# M2Sxxx register map
Vendor: Microsemi; Series: SmartFusion2; File version: 2.0.32
CPU: CM3 r2p1, little endian, MPU, no FPU, 4 interrupt priority bits
Registers are 32-bit, read-write, no defined reset value unless marked. A register's access mark holds for its fields unless they carry their own. Offsets are from the block's base; [hi:lo] are bit positions; {n}, {i} and the like mark numbered series; 'fields as' and 'values as' point back to an identical list.

## MDDR — No description provided for this peripheral
Base 0x40020800
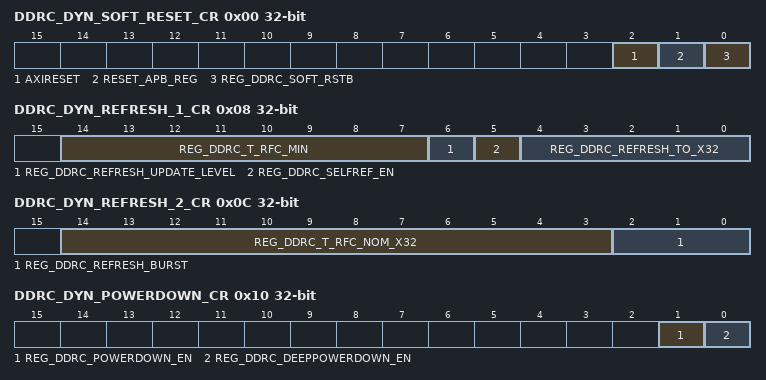
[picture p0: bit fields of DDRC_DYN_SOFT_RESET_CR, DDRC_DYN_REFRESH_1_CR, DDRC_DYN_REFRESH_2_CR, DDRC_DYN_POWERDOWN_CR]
0x00 DDRC_DYN_SOFT_RESET_CR — No description provided for this register
  [2] AXIRESET — No description provided for this field
  [1] RESET_APB_REG — No description provided for this field
  [0] REG_DDRC_SOFT_RSTB — No description provided for this field
0x08 DDRC_DYN_REFRESH_1_CR — No description provided for this register
  [14:7] REG_DDRC_T_RFC_MIN — No description provided for this field
  [6] REG_DDRC_REFRESH_UPDATE_LEVEL — No description provided for this field
  [5] REG_DDRC_SELFREF_EN — No description provided for this field
  [4:0] REG_DDRC_REFRESH_TO_X32 — No description provided for this field
0x0C DDRC_DYN_REFRESH_2_CR — No description provided for this register
  [14:3] REG_DDRC_T_RFC_NOM_X32 — No description provided for this field
  [2:0] REG_DDRC_REFRESH_BURST — No description provided for this field
0x10 DDRC_DYN_POWERDOWN_CR — No description provided for this register
  [1] REG_DDRC_POWERDOWN_EN — No description provided for this field
  [0] REG_DDRC_DEEPPOWERDOWN_EN — No description provided for this field
0x14 DDRC_DYN_DEBUG_CR — No description provided for this register
  [0] REG_DDRC_DIS_DQ — No description provided for this field
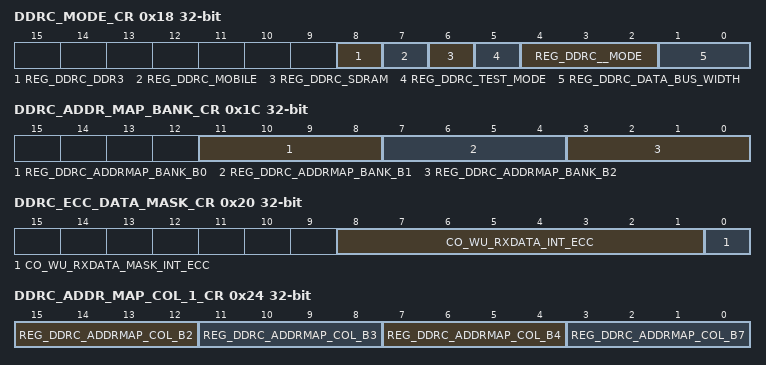
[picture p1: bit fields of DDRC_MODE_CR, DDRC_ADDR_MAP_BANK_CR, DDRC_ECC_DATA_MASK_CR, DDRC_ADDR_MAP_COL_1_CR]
0x18 DDRC_MODE_CR — No description provided for this register
  [8] REG_DDRC_DDR3 — No description provided for this field
  [7] REG_DDRC_MOBILE — No description provided for this field
  [6] REG_DDRC_SDRAM — No description provided for this field
  [5] REG_DDRC_TEST_MODE — No description provided for this field
  [4:2] REG_DDRC__MODE — No description provided for this field
  [1:0] REG_DDRC_DATA_BUS_WIDTH — No description provided for this field
0x1C DDRC_ADDR_MAP_BANK_CR — No description provided for this register
  [11:8] REG_DDRC_ADDRMAP_BANK_B0 — No description provided for this field
  [7:4] REG_DDRC_ADDRMAP_BANK_B1 — No description provided for this field
  [3:0] REG_DDRC_ADDRMAP_BANK_B2 — No description provided for this field
0x20 DDRC_ECC_DATA_MASK_CR — No description provided for this register
  [8:1] CO_WU_RXDATA_INT_ECC — No description provided for this field
  [0] CO_WU_RXDATA_MASK_INT_ECC — No description provided for this field
0x24 DDRC_ADDR_MAP_COL_1_CR — No description provided for this register
  [15:12] REG_DDRC_ADDRMAP_COL_B2 — No description provided for this field
  [11:8] REG_DDRC_ADDRMAP_COL_B3 — No description provided for this field
  [7:4] REG_DDRC_ADDRMAP_COL_B4 — No description provided for this field
  [3:0] REG_DDRC_ADDRMAP_COL_B7 — No description provided for this field
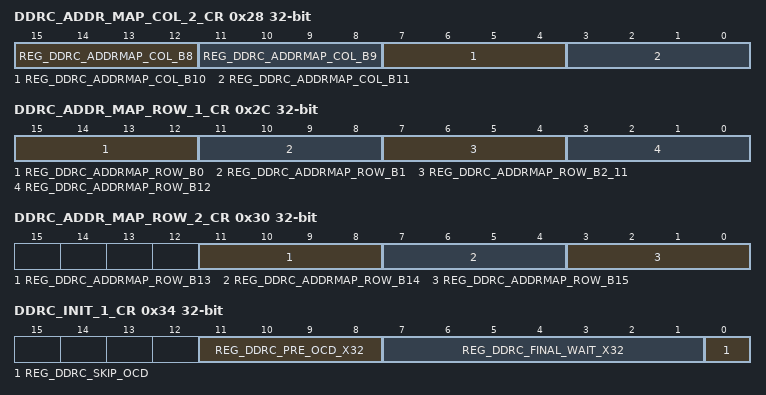
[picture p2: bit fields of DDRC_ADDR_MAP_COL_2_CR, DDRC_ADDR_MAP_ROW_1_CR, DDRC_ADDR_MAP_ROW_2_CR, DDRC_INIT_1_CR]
0x28 DDRC_ADDR_MAP_COL_2_CR — No description provided for this register
  [47-4n:44-4n] REG_DDRC_ADDRMAP_COL_B{n} (n=8..11) — No description provided for this field
0x2C DDRC_ADDR_MAP_ROW_1_CR — No description provided for this register
  [15:12] REG_DDRC_ADDRMAP_ROW_B0 — No description provided for this field
  [11:8] REG_DDRC_ADDRMAP_ROW_B1 — No description provided for this field
  [7:4] REG_DDRC_ADDRMAP_ROW_B2_11 — No description provided for this field
  [3:0] REG_DDRC_ADDRMAP_ROW_B12 — No description provided for this field
0x30 DDRC_ADDR_MAP_ROW_2_CR — No description provided for this register
  [11:8] REG_DDRC_ADDRMAP_ROW_B13 — No description provided for this field
  [7:4] REG_DDRC_ADDRMAP_ROW_B14 — No description provided for this field
  [3:0] REG_DDRC_ADDRMAP_ROW_B15 — No description provided for this field
0x34 DDRC_INIT_1_CR — No description provided for this register
  [11:8] REG_DDRC_PRE_OCD_X32 — No description provided for this field
  [7:1] REG_DDRC_FINAL_WAIT_X32 — No description provided for this field
  [0] REG_DDRC_SKIP_OCD — No description provided for this field
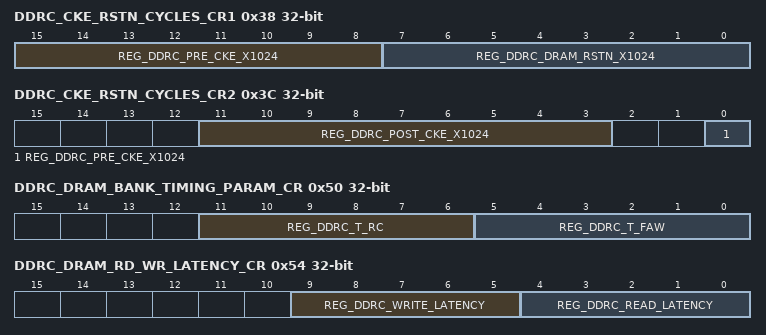
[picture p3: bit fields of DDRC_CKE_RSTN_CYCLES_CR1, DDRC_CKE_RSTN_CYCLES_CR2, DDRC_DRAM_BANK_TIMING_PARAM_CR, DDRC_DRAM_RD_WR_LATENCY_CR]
0x38 DDRC_CKE_RSTN_CYCLES_CR1 — No description provided for this register
  [15:8] REG_DDRC_PRE_CKE_X1024 — No description provided for this field
  [7:0] REG_DDRC_DRAM_RSTN_X1024 — No description provided for this field
0x3C DDRC_CKE_RSTN_CYCLES_CR2 — No description provided for this register
  [11:3] REG_DDRC_POST_CKE_X1024 — No description provided for this field
  [0] REG_DDRC_PRE_CKE_X1024 — No description provided for this field
0x40 DDRC_INIT_MR_CR — No description provided for this register
  [15:0] REG_DDRC_MR — No description provided for this field
0x44 DDRC_INIT_EMR_CR — No description provided for this register
  [15:0] REG_DDRC_EMR — No description provided for this field
0x48 DDRC_INIT_EMR2_CR — No description provided for this register
  [15:0] REG_DDRC_EMR2 — No description provided for this field
0x4C DDRC_INIT_EMR3_CR — No description provided for this register
  [15:0] REG_DDRC_EMR3 — No description provided for this field
0x50 DDRC_DRAM_BANK_TIMING_PARAM_CR — No description provided for this register
  [11:6] REG_DDRC_T_RC — No description provided for this field
  [5:0] REG_DDRC_T_FAW — No description provided for this field
0x54 DDRC_DRAM_RD_WR_LATENCY_CR — No description provided for this register
  [9:5] REG_DDRC_WRITE_LATENCY — No description provided for this field
  [4:0] REG_DDRC_READ_LATENCY — No description provided for this field
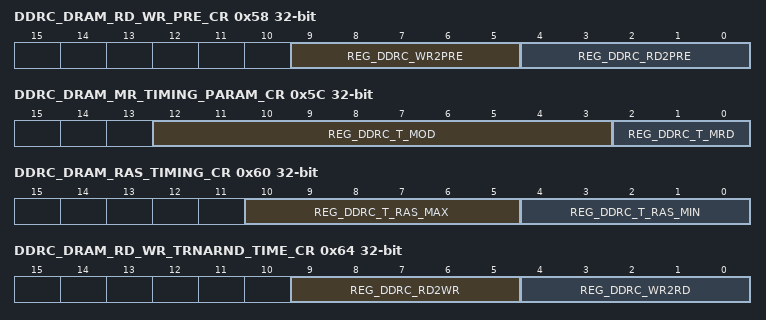
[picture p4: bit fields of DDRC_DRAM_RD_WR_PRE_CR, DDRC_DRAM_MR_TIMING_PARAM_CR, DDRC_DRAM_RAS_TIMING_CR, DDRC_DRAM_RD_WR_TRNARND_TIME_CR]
0x58 DDRC_DRAM_RD_WR_PRE_CR — No description provided for this register
  [9:5] REG_DDRC_WR2PRE — No description provided for this field
  [4:0] REG_DDRC_RD2PRE — No description provided for this field
0x5C DDRC_DRAM_MR_TIMING_PARAM_CR — No description provided for this register
  [12:3] REG_DDRC_T_MOD — No description provided for this field
  [2:0] REG_DDRC_T_MRD — No description provided for this field
0x60 DDRC_DRAM_RAS_TIMING_CR — No description provided for this register
  [10:5] REG_DDRC_T_RAS_MAX — No description provided for this field
  [4:0] REG_DDRC_T_RAS_MIN — No description provided for this field
0x64 DDRC_DRAM_RD_WR_TRNARND_TIME_CR — No description provided for this register
  [9:5] REG_DDRC_RD2WR — No description provided for this field
  [4:0] REG_DDRC_WR2RD — No description provided for this field
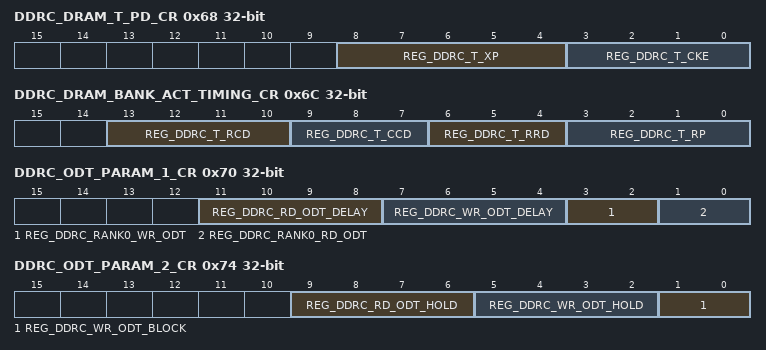
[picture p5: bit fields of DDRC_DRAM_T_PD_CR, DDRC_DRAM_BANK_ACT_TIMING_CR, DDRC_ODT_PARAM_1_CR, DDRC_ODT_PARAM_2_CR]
0x68 DDRC_DRAM_T_PD_CR — No description provided for this register
  [8:4] REG_DDRC_T_XP — No description provided for this field
  [3:0] REG_DDRC_T_CKE — No description provided for this field
0x6C DDRC_DRAM_BANK_ACT_TIMING_CR — No description provided for this register
  [13:10] REG_DDRC_T_RCD — No description provided for this field
  [9:7] REG_DDRC_T_CCD — No description provided for this field
  [6:4] REG_DDRC_T_RRD — No description provided for this field
  [3:0] REG_DDRC_T_RP — No description provided for this field
0x70 DDRC_ODT_PARAM_1_CR — No description provided for this register
  [11:8] REG_DDRC_RD_ODT_DELAY — No description provided for this field
  [7:4] REG_DDRC_WR_ODT_DELAY — No description provided for this field
  [3:2] REG_DDRC_RANK0_WR_ODT — No description provided for this field
  [1:0] REG_DDRC_RANK0_RD_ODT — No description provided for this field
0x74 DDRC_ODT_PARAM_2_CR — No description provided for this register
  [9:6] REG_DDRC_RD_ODT_HOLD — No description provided for this field
  [5:2] REG_DDRC_WR_ODT_HOLD — No description provided for this field
  [1:0] REG_DDRC_WR_ODT_BLOCK — No description provided for this field
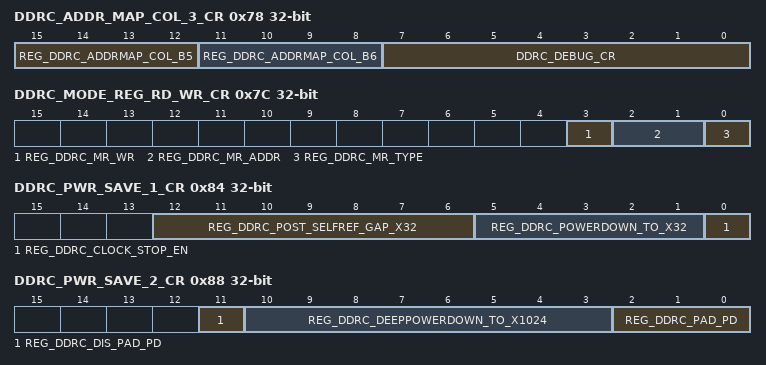
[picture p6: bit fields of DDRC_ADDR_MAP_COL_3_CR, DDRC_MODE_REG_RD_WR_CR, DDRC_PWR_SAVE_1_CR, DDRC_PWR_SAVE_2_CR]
0x78 DDRC_ADDR_MAP_COL_3_CR — No description provided for this register
  [15:12] REG_DDRC_ADDRMAP_COL_B5 — No description provided for this field
  [11:8] REG_DDRC_ADDRMAP_COL_B6 — No description provided for this field
  [7:0] DDRC_DEBUG_CR — No description provided for this field
0x7C DDRC_MODE_REG_RD_WR_CR — No description provided for this register
  [3] REG_DDRC_MR_WR — No description provided for this field
  [2:1] REG_DDRC_MR_ADDR — No description provided for this field
  [0] REG_DDRC_MR_TYPE — No description provided for this field
0x80 DDRC_MODE_REG_DATA_CR — No description provided for this register
  [15:0] REG_DDRC_MR_DATA — No description provided for this field
0x84 DDRC_PWR_SAVE_1_CR — No description provided for this register
  [12:6] REG_DDRC_POST_SELFREF_GAP_X32 — No description provided for this field
  [5:1] REG_DDRC_POWERDOWN_TO_X32 — No description provided for this field
  [0] REG_DDRC_CLOCK_STOP_EN — No description provided for this field
0x88 DDRC_PWR_SAVE_2_CR — No description provided for this register
  [11] REG_DDRC_DIS_PAD_PD — No description provided for this field
  [10:3] REG_DDRC_DEEPPOWERDOWN_TO_X1024 — No description provided for this field
  [2:0] REG_DDRC_PAD_PD — No description provided for this field
0x8C DDRC_ZQ_LONG_TIME_CR — No description provided for this register
  [9:0] REG_DDRC_T_ZQ_LONG_NOP — No description provided for this field
0x90 DDRC_ZQ_SHORT_TIME_CR — No description provided for this register
  [9:0] REG_DDRC_T_ZQ_SHORT_NOP — No description provided for this field
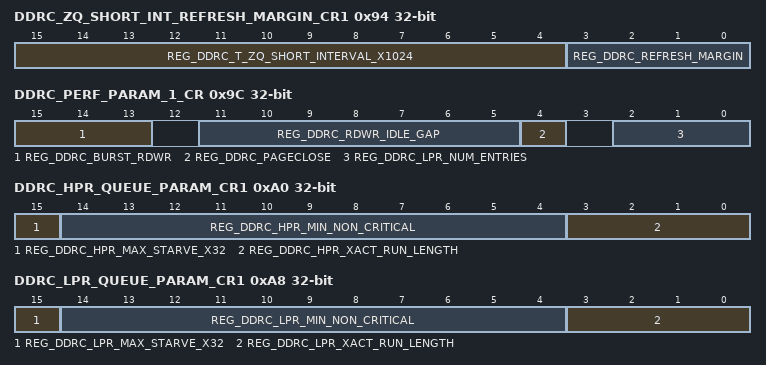
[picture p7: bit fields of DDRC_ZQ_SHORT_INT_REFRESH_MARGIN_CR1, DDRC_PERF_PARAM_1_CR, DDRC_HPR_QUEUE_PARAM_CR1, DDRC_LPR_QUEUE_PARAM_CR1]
0x94 DDRC_ZQ_SHORT_INT_REFRESH_MARGIN_CR1 — No description provided for this register
  [15:4] REG_DDRC_T_ZQ_SHORT_INTERVAL_X1024 — No description provided for this field
  [3:0] REG_DDRC_REFRESH_MARGIN — No description provided for this field
0x98 DDRC_ZQ_SHORT_INT_REFRESH_MARGIN_CR2 — No description provided for this register
  [7:0] REG_DDRC_T_ZQ_SHORT_INTERVAL_X1024 — No description provided for this field
0x9C DDRC_PERF_PARAM_1_CR — No description provided for this register
  [15:13] REG_DDRC_BURST_RDWR — No description provided for this field
  [11:5] REG_DDRC_RDWR_IDLE_GAP — No description provided for this field
  [4] REG_DDRC_PAGECLOSE — No description provided for this field
  [2:0] REG_DDRC_LPR_NUM_ENTRIES — No description provided for this field
0xA0 DDRC_HPR_QUEUE_PARAM_CR1 — No description provided for this register
  [15] REG_DDRC_HPR_MAX_STARVE_X32 — No description provided for this field
  [14:4] REG_DDRC_HPR_MIN_NON_CRITICAL — No description provided for this field
  [3:0] REG_DDRC_HPR_XACT_RUN_LENGTH — No description provided for this field
0xA4 DDRC_HPR_QUEUE_PARAM_CR2 — No description provided for this register
  [10:0] REG_DDRC_HPR_MAX_STARVE_X32 — No description provided for this field
0xA8 DDRC_LPR_QUEUE_PARAM_CR1 — No description provided for this register
  [15] REG_DDRC_LPR_MAX_STARVE_X32 — No description provided for this field
  [14:4] REG_DDRC_LPR_MIN_NON_CRITICAL — No description provided for this field
  [3:0] REG_DDRC_LPR_XACT_RUN_LENGTH — No description provided for this field
0xAC DDRC_LPR_QUEUE_PARAM_CR2 — No description provided for this register
  [10:0] REG_DDRC_LPR_MAX_STARVE_X32 — No description provided for this field
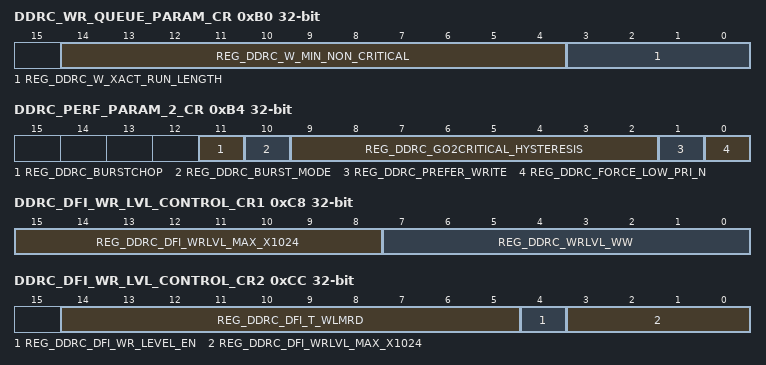
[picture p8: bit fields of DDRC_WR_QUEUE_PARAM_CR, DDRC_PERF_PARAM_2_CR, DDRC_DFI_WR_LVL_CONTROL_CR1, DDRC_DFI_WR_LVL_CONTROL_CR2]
0xB0 DDRC_WR_QUEUE_PARAM_CR — No description provided for this register
  [14:4] REG_DDRC_W_MIN_NON_CRITICAL — No description provided for this field
  [3:0] REG_DDRC_W_XACT_RUN_LENGTH — No description provided for this field
0xB4 DDRC_PERF_PARAM_2_CR — No description provided for this register
  [11] REG_DDRC_BURSTCHOP — No description provided for this field
  [10] REG_DDRC_BURST_MODE — No description provided for this field
  [9:2] REG_DDRC_GO2CRITICAL_HYSTERESIS — No description provided for this field
  [1] REG_DDRC_PREFER_WRITE — No description provided for this field
  [0] REG_DDRC_FORCE_LOW_PRI_N — No description provided for this field
0xB8 DDRC_PERF_PARAM_3_CR — No description provided for this register
  [0] REG_DDRC_EN_2T_TIMING_MODE — No description provided for this field
0xBC DDRC_DFI_RDDATA_EN_CR — No description provided for this register
  [4:0] REG_DDRC_DFI_T_RDDATA_EN — No description provided for this field
0xC0 DDRC_DFI_MIN_CTRLUPD_TIMING_CR — No description provided for this register
  [9:0] REG_DDRC_DFI_T_CTRLUP_MIN — No description provided for this field
0xC4 DDRC_DFI_MAX_CTRLUPD_TIMING_CR — No description provided for this register
  [9:0] REG_DDRC_DFI_T_CTRLUP_MAX — No description provided for this field
0xC8 DDRC_DFI_WR_LVL_CONTROL_CR1 — No description provided for this register
  [15:8] REG_DDRC_DFI_WRLVL_MAX_X1024 — No description provided for this field
  [7:0] REG_DDRC_WRLVL_WW — No description provided for this field
0xCC DDRC_DFI_WR_LVL_CONTROL_CR2 — No description provided for this register
  [14:5] REG_DDRC_DFI_T_WLMRD — No description provided for this field
  [4] REG_DDRC_DFI_WR_LEVEL_EN — No description provided for this field
  [3:0] REG_DDRC_DFI_WRLVL_MAX_X1024 — No description provided for this field
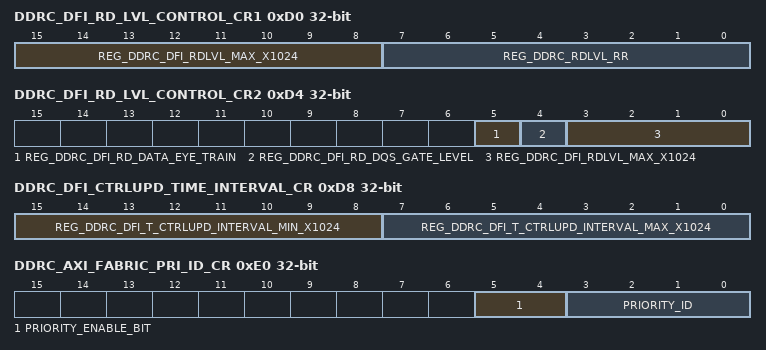
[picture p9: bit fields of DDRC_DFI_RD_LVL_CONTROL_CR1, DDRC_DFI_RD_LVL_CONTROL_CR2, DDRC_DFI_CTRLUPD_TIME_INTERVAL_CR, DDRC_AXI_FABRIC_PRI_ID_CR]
0xD0 DDRC_DFI_RD_LVL_CONTROL_CR1 — No description provided for this register
  [15:8] REG_DDRC_DFI_RDLVL_MAX_X1024 — No description provided for this field
  [7:0] REG_DDRC_RDLVL_RR — No description provided for this field
0xD4 DDRC_DFI_RD_LVL_CONTROL_CR2 — No description provided for this register
  [5] REG_DDRC_DFI_RD_DATA_EYE_TRAIN — No description provided for this field
  [4] REG_DDRC_DFI_RD_DQS_GATE_LEVEL — No description provided for this field
  [3:0] REG_DDRC_DFI_RDLVL_MAX_X1024 — No description provided for this field
0xD8 DDRC_DFI_CTRLUPD_TIME_INTERVAL_CR — No description provided for this register
  [15:8] REG_DDRC_DFI_T_CTRLUPD_INTERVAL_MIN_X1024 — No description provided for this field
  [7:0] REG_DDRC_DFI_T_CTRLUPD_INTERVAL_MAX_X1024 — No description provided for this field
0xE0 DDRC_AXI_FABRIC_PRI_ID_CR — No description provided for this register
  [5:4] PRIORITY_ENABLE_BIT ro — No description provided for this field
  [3:0] PRIORITY_ID — No description provided for this field
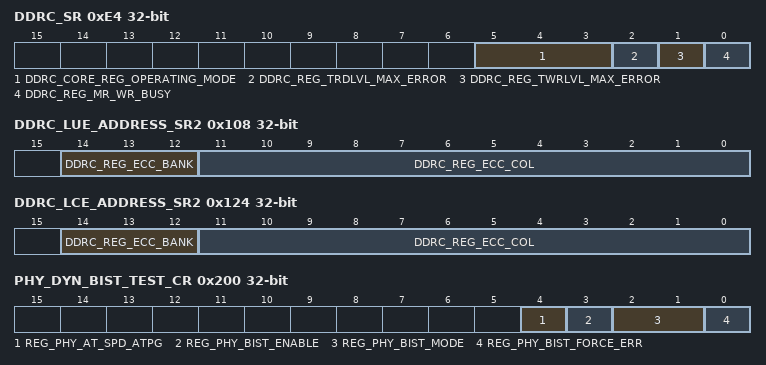
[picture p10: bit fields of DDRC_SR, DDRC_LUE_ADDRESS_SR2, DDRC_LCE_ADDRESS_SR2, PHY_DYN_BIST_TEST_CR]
0xE4 DDRC_SR — No description provided for this register
  [5:3] DDRC_CORE_REG_OPERATING_MODE ro — No description provided for this field
  [2] DDRC_REG_TRDLVL_MAX_ERROR ro — No description provided for this field
  [1] DDRC_REG_TWRLVL_MAX_ERROR ro — No description provided for this field
  [0] DDRC_REG_MR_WR_BUSY ro — No description provided for this field
0xE8 DDRC_SINGLE_ERR_CNT_STATUS_SR — No description provided for this register
  [31:0] DDRC_SINGLE_ERR_CNT_STATUS_REG ro — No description provided for this field
0xEC DDRC_DOUBLE_ERR_CNT_STATUS_SR — No description provided for this register
  [31:0] DDRC_DOUBLE_ERR_CNT_STATUS_REG ro — No description provided for this field
{0xEC+4i} DDRC_LUE_SYNDROME_SR{i} (i=1..4) — No description provided for this register
  [15:0] DDRC_REG_ECC_SYNDROMES ro — No description provided for this field
0x100 DDRC_LUE_SYNDROME_SR5 — No description provided for this register
  [7:0] DDRC_REG_ECC_SYNDROMES ro — No description provided for this field
0x104 DDRC_LUE_ADDRESS_SR1 — No description provided for this register
  [15:0] DDRC_REG_ECC_ROW ro — No description provided for this field
0x108 DDRC_LUE_ADDRESS_SR2 — No description provided for this register
  [14:12] DDRC_REG_ECC_BANK ro — No description provided for this field
  [11:0] DDRC_REG_ECC_COL ro — No description provided for this field
{0x108+4i} DDRC_LCE_SYNDROME_SR{i} (i=1..4) — No description provided for this register
  fields as DDRC_LUE_SYNDROME_SR1
0x11C DDRC_LCE_SYNDROME_SR5 — No description provided for this register
  fields as DDRC_LUE_SYNDROME_SR5
0x120 DDRC_LCE_ADDRESS_SR1 — No description provided for this register
  [15:0] DDRC_REG_ECC_ROW ro — No description provided for this field
0x124 DDRC_LCE_ADDRESS_SR2 — No description provided for this register
  fields as DDRC_LUE_ADDRESS_SR2
0x128 DDRC_LCB_NUMBER_SR — No description provided for this register
  [6:0] DDRC_LCB_BIT_NUM ro — No description provided for this field
{0x128+4i} DDRC_LCB_MASK_SR{i} (i=1..4) — No description provided for this register
  [15:0] DDRC_LCB_MASK ro — No description provided for this field
0x13C DDRC_ECC_INT_SR — No description provided for this register
  [2:0] DDRC_ECC_STATUS_SR ro — No description provided for this field
0x140 DDRC_ECC_INT_CLR_REG — No description provided for this register
  [0] DDRC_ECC_INT_CLR_REG — No description provided for this field
0x144 ECC_OUTPUT_DATA_SR — No description provided for this register
  [7:0] ECC_OUTPUT_DATA_SR — No description provided for this field
0x200 PHY_DYN_BIST_TEST_CR — No description provided for this register
  [4] REG_PHY_AT_SPD_ATPG — No description provided for this field
  [3] REG_PHY_BIST_ENABLE — No description provided for this field
  [2:1] REG_PHY_BIST_MODE — No description provided for this field
  [0] REG_PHY_BIST_FORCE_ERR — No description provided for this field
0x204 PHY_DYN_BIST_TEST_ERRCLR_CR1 — No description provided for this register
  [15:0] REG_PHY_BIST_ERR_CLR — No description provided for this field
0x208 PHY_DYN_BIST_TEST_ERRCLR_CR2 — No description provided for this register
  [15:0] REG_PHY_BIST_ERR_CLR — No description provided for this field
0x20C PHY_DYN_BIST_TEST_ERRCLR_CR3 — No description provided for this register
  [11:0] REG_PHY_BIST_ERR_CLR — No description provided for this field
0x210 PHY_BIST_TEST_SHIFT_PATTERN_CR1 — No description provided for this register
  [15:0] REG_PHY_BIST_SHIFT_DQ — No description provided for this field
0x214 PHY_BIST_TEST_SHIFT_PATTERN_CR2 — No description provided for this register
  fields as PHY_BIST_TEST_SHIFT_PATTERN_CR1
0x218 PHY_BIST_TEST_SHIFT_PATTERN_CR3 — No description provided for this register
  [11:0] REG_PHY_BIST_SHIFT_DQ — No description provided for this field
0x21C PHY_LOOPBACK_TEST_CR — No description provided for this register
  [0] REG_PHY_LOOPBACK — No description provided for this field
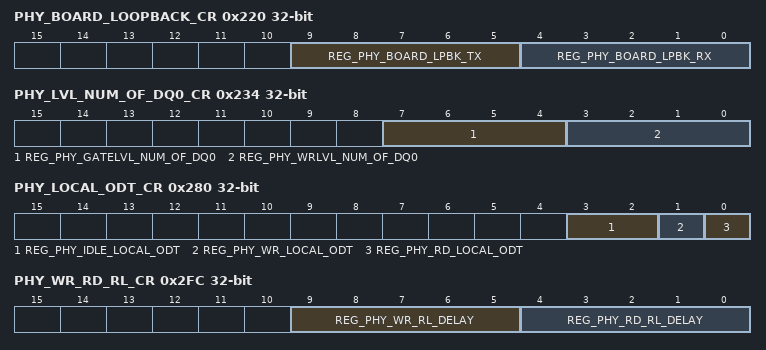
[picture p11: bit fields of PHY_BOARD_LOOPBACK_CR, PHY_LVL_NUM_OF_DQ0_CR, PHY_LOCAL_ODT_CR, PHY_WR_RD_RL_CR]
0x220 PHY_BOARD_LOOPBACK_CR — No description provided for this register
  [9:5] REG_PHY_BOARD_LPBK_TX — No description provided for this field
  [4:0] REG_PHY_BOARD_LPBK_RX — No description provided for this field
0x224 PHY_CTRL_SLAVE_RATIO_CR — No description provided for this register
  [9:0] REG_PHY_CTRL_SLAVE_RATIO — No description provided for this field
0x228 PHY_CTRL_SLAVE_FORCE_CR — No description provided for this register
  [0] REG_PHY_CTRL_SLAVE_FORCE — No description provided for this field
0x22C PHY_CTRL_SLAVE_DELAY_CR — No description provided for this register
  [8:0] REG_PHY_CTRL_SLAVE_DELAY — No description provided for this field
0x230 PHY_DATA_SLICE_IN_USE_CR — No description provided for this register
  [8:0] REG_PHY_DATA_SLICE_IN_USE — No description provided for this field
0x234 PHY_LVL_NUM_OF_DQ0_CR — No description provided for this register
  [7:4] REG_PHY_GATELVL_NUM_OF_DQ0 — No description provided for this field
  [3:0] REG_PHY_WRLVL_NUM_OF_DQ0 — No description provided for this field
0x238 PHY_DQ_OFFSET_CR1 — No description provided for this register
  [15:0] REG_PHY_DQ_OFFSET — No description provided for this field
0x23C PHY_DQ_OFFSET_CR2 — No description provided for this register
  [15:0] REG_PHY_DQ_OFFSET — No description provided for this field
0x240 PHY_DQ_OFFSET_CR3 — No description provided for this register
  [2:0] REG_PHY_DQ_OFFSET — No description provided for this field
0x244 PHY_DIS_CALIB_RST_Q — No description provided for this register
  [0] REG_PHY_DIS_CALIB_RST — No description provided for this field
0x248 PHY_DLL_LOCK_DIFF_CR — No description provided for this register
  [0] REG_PHY_DLL_LOCK_DIFF — No description provided for this field
0x24C PHY_FIFO_WE_IN_DELAY_CR1 — No description provided for this register
  [15:0] REG_PHY_FIFO_WE_IN_DELAY — No description provided for this field
0x250 PHY_FIFO_WE_IN_DELAY_CR2 — No description provided for this register
  fields as PHY_FIFO_WE_IN_DELAY_CR1
0x254 PHY_FIFO_WE_IN_DELAY_CR3 — No description provided for this register
  [12:0] REG_PHY_FIFO_WE_IN_DELAY — No description provided for this field
0x258 PHY_FIFO_WE_IN_FORCE_Q — No description provided for this register
  [4:0] REG_PHY_FIFO_WE_IN_FORCE — No description provided for this field
{0x258+4i} PHY_FIFO_WE_SLAVE_RATIO_CR{i} (i=1..3) — No description provided for this register
  [15:0] REG_PHY_FIFO_WE_SLAVE_RATIO — No description provided for this field
0x268 PHY_FIFO_WE_SLAVE_RATIO_CR4 — No description provided for this register
  [6:0] REG_PHY_FIFO_WE_SLAVE_RATIO — No description provided for this field
0x26C PHY_GATELVL_INIT_MODE_CR — No description provided for this register
  [0] REG_PHY_GATELVL_INIT_MODE — No description provided for this field
{0x26C+4i} PHY_GATELVL_INIT_RATIO_CR{i} (i=1..3) — No description provided for this register
  [15:0] REG_PHY_GATELVL_INIT_RATIO — No description provided for this field
0x27C PHY_GATELVL_INIT_RATIO_CR4 — No description provided for this register
  [6:0] REG_PHY_GATELVL_INIT_RATIO — No description provided for this field
0x280 PHY_LOCAL_ODT_CR — No description provided for this register
  [3:2] REG_PHY_IDLE_LOCAL_ODT — No description provided for this field
  [1] REG_PHY_WR_LOCAL_ODT — No description provided for this field
  [0] REG_PHY_RD_LOCAL_ODT — No description provided for this field
0x284 PHY_INVERT_CLKOUT_CR — No description provided for this register
  [0] REG_PHY_INVERT_CLKOUT — No description provided for this field
0x288 PHY_RD_DQS_SLAVE_DELAY_CR1 — No description provided for this register
  [15:0] REG_PHY_RD_DQS_SLAVE_DELAY — No description provided for this field
0x28C PHY_RD_DQS_SLAVE_DELAY_CR2 — No description provided for this register
  fields as PHY_RD_DQS_SLAVE_DELAY_CR1
0x290 PHY_RD_DQS_SLAVE_DELAY_CR3 — No description provided for this register
  [12:0] REG_PHY_RD_DQS_SLAVE_DELAY — No description provided for this field
0x294 PHY_RD_DQS_SLAVE_FORCE_CR — No description provided for this register
  [0] REG_PHY_RD_DQS_SLAVE_FORCE — No description provided for this field
{0x294+4i} PHY_RD_DQS_SLAVE_RATIO_CR{i} (i=1..3) — No description provided for this register
  [15:0] REG_PHY_RD_DQS_SLAVE_RATIO — No description provided for this field
0x2A4 PHY_RD_DQS_SLAVE_RATIO_CR4 — No description provided for this register
  [1:0] REG_PHY_RD_DQS_SLAVE_RATIO — No description provided for this field
0x2A8 PHY_WR_DQS_SLAVE_DELAY_CR1 — No description provided for this register
  [15:0] REG_PHY_WR_DQS_SLAVE_DELAY — No description provided for this field
0x2AC PHY_WR_DQS_SLAVE_DELAY_CR2 — No description provided for this register
  fields as PHY_WR_DQS_SLAVE_DELAY_CR1
0x2B0 PHY_WR_DQS_SLAVE_DELAY_CR3 — No description provided for this register
  [12:0] REG_PHY_WR_DQS_SLAVE_DELAY — No description provided for this field
0x2B4 PHY_WR_DQS_SLAVE_FORCE_CR — No description provided for this register
  [4:0] REG_PHY_WR_DQS_SLAVE_FORCE — No description provided for this field
{0x2B4+4i} PHY_WR_DQS_SLAVE_RATIO_CR{i} (i=1..3) — No description provided for this register
  [15:0] REG_PHY_WR_DQS_SLAVE_RATIO — No description provided for this field
0x2C4 PHY_WR_DQS_SLAVE_RATIO_CR4 — No description provided for this register
  [1:0] REG_PHY_WR_DQS_SLAVE_RATIO — No description provided for this field
0x2C8 PHY_WR_DATA_SLAVE_DELAY_CR1 — No description provided for this register
  [15:0] REG_PHY_WR_DATA_SLAVE_DELAY — No description provided for this field
0x2CC PHY_WR_DATA_SLAVE_DELAY_CR2 — No description provided for this register
  fields as PHY_WR_DATA_SLAVE_DELAY_CR1
0x2D0 PHY_WR_DATA_SLAVE_DELAY_CR3 — No description provided for this register
  [12:0] REG_PHY_WR_DATA_SLAVE_DELAY — No description provided for this field
0x2D4 PHY_WR_DATA_SLAVE_FORCE_CR — No description provided for this register
  [4:0] REG_PHY_WR_DATA_SLAVE_FORCE — No description provided for this field
{0x2D4+4i} PHY_WR_DATA_SLAVE_RATIO_CR{i} (i=1..3) — No description provided for this register
  [15:0] REG_PHY_WR_DATA_SLAVE_RATIO — No description provided for this field
0x2E4 PHY_WR_DATA_SLAVE_RATIO_CR4 — No description provided for this register
  [1:0] REG_PHY_WR_DATA_SLAVE_RATIO — No description provided for this field
0x2E8 PHY_WRLVL_INIT_MODE_CR — No description provided for this register
  [0] REG_PHY_WRLVL_INIT_MODE — No description provided for this field
{0x2E8+4i} PHY_WRLVL_INIT_RATIO_CR{i} (i=1..3) — No description provided for this register
  [15:0] REG_PHY_WRLVL_INIT_MODE — No description provided for this field
0x2F8 PHY_WRLVL_INIT_RATIO_CR4 — No description provided for this register
  [1:0] REG_PHY_WRLVL_INIT_MODE — No description provided for this field
0x2FC PHY_WR_RD_RL_CR — No description provided for this register
  [9:5] REG_PHY_WR_RL_DELAY — No description provided for this field
  [4:0] REG_PHY_RD_RL_DELAY — No description provided for this field
0x300 PHY_DYN_RDC_FIFO_RST_ERR_CNT_CLR_CR — No description provided for this register
  [0] REG_PHY_RDC_FIFO_RST_ERR_CNT_CLR — No description provided for this field
0x304 PHY_RDC_WE_TO_RE_DELAY_CR — No description provided for this register
  [3:0] REG_PHY_RDC_WE_TO_RE_DELAY — No description provided for this field
0x308 PHY_USE_FIXED_RE_CR — No description provided for this register
  [0] REG_PHY_USE_FIXED_RE — No description provided for this field
0x30C PHY_USE_RANK0_DELAYS_CR — No description provided for this register
  [0] REG_PHY_USE_RANK0_DELAYS — No description provided for this field
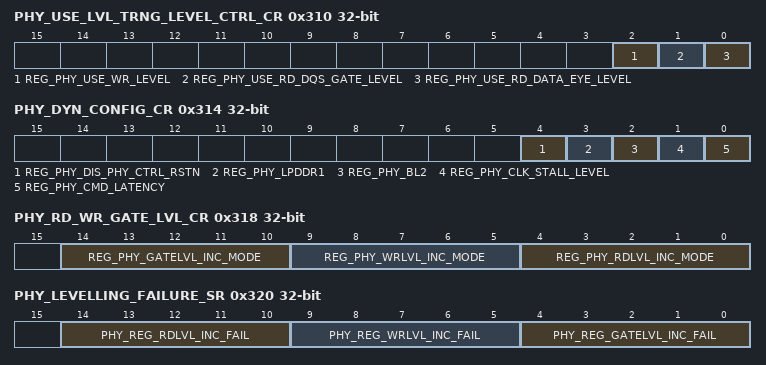
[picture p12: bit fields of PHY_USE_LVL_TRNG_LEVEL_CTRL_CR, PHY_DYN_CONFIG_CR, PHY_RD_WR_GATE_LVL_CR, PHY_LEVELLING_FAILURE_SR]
0x310 PHY_USE_LVL_TRNG_LEVEL_CTRL_CR — No description provided for this register
  [2] REG_PHY_USE_WR_LEVEL — No description provided for this field
  [1] REG_PHY_USE_RD_DQS_GATE_LEVEL — No description provided for this field
  [0] REG_PHY_USE_RD_DATA_EYE_LEVEL — No description provided for this field
0x314 PHY_DYN_CONFIG_CR — No description provided for this register
  [4] REG_PHY_DIS_PHY_CTRL_RSTN — No description provided for this field
  [3] REG_PHY_LPDDR1 — No description provided for this field
  [2] REG_PHY_BL2 — No description provided for this field
  [1] REG_PHY_CLK_STALL_LEVEL — No description provided for this field
  [0] REG_PHY_CMD_LATENCY — No description provided for this field
0x318 PHY_RD_WR_GATE_LVL_CR — No description provided for this register
  [14:10] REG_PHY_GATELVL_INC_MODE — No description provided for this field
  [9:5] REG_PHY_WRLVL_INC_MODE — No description provided for this field
  [4:0] REG_PHY_RDLVL_INC_MODE — No description provided for this field
0x31C PHY_DYN_RESET_CR — No description provided for this register
  [0] PHY_RESET — No description provided for this field
0x320 PHY_LEVELLING_FAILURE_SR — No description provided for this register
  [14:10] PHY_REG_RDLVL_INC_FAIL ro — No description provided for this field
  [9:5] PHY_REG_WRLVL_INC_FAIL ro — No description provided for this field
  [4:0] PHY_REG_GATELVL_INC_FAIL ro — No description provided for this field
0x324 PHY_BIST_ERROR_SR1 — No description provided for this register
  [15:0] PHY_REG_BIST_ERR ro — No description provided for this field
0x328 PHY_BIST_ERROR_SR2 — No description provided for this register
  [15:0] PHY_REG_BIST_ERR ro — No description provided for this field
0x32C PHY_BIST_ERROR_SR3 — No description provided for this register
  [12:0] PHY_REG_BIST_ERR ro — No description provided for this field
{0x32C+4i} PHY_WRLVL_DQS_RATIO_SR{i} (i=1..3) — No description provided for this register
  [15:0] PHY_REG_WRLVL_DQS_RATIO ro — No description provided for this field
0x33C PHY_WRLVL_DQS_RATIO_SR4 — No description provided for this register
  [1:0] PHY_REG_WRLVL_DQS_RATIO ro — No description provided for this field
{0x33C+4i} PHY_WRLVL_DQ_RATIO_SR{i} (i=1..3) — No description provided for this register
  [15:0] PHY_REG_WRLVL_DQ_RATIO ro — No description provided for this field
0x34C PHY_WRLVL_DQ_RATIO_SR4 — No description provided for this register
  [1:0] PHY_REG_WRLVL_DQ_RATIO ro — No description provided for this field
{0x34C+4i} PHY_RDLVL_DQS_RATIO_SR{i} (i=1..3) — No description provided for this register
  [15:0] PHY_REG_RDLVL_DQS_RATIO ro — No description provided for this field
0x35C PHY_RDLVL_DQS_RATIO_SR4 — No description provided for this register
  [1:0] PHY_REG_RDLVL_DQS_RATIO ro — No description provided for this field
0x360 PHY_FIFO_SR1 — No description provided for this register
  [15:0] PHY_REG_RDLVL_FIFOWEIN_RATIO ro — No description provided for this field
0x364 PHY_FIFO_SR2 — No description provided for this register
  fields as PHY_FIFO_SR1
0x368 PHY_FIFO_SR3 — No description provided for this register
  [15:0] PHY_RDLVL_FIFOWEIN_RATIO ro — No description provided for this field
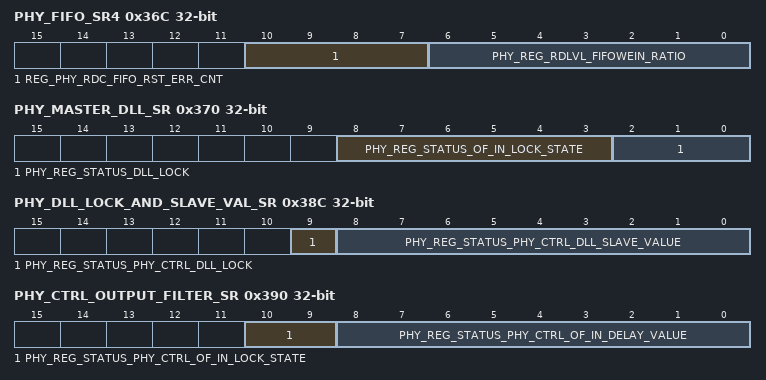
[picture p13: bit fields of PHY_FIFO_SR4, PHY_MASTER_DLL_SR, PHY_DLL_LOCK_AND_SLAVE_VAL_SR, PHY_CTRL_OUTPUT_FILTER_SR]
0x36C PHY_FIFO_SR4 — No description provided for this register
  [10:7] REG_PHY_RDC_FIFO_RST_ERR_CNT ro — No description provided for this field
  [6:0] PHY_REG_RDLVL_FIFOWEIN_RATIO ro — No description provided for this field
0x370 PHY_MASTER_DLL_SR — No description provided for this register
  [8:3] PHY_REG_STATUS_OF_IN_LOCK_STATE ro — No description provided for this field
  [2:0] PHY_REG_STATUS_DLL_LOCK ro — No description provided for this field
0x374 PHY_DLL_SLAVE_VALUE_SR1 — No description provided for this register
  [15:0] PHY_REG_STATUS_DLL_SLAVE_VALUE ro — No description provided for this field
0x378 PHY_DLL_SLAVE_VALUE_SR2 — No description provided for this register
  [10:0] PHY_REG_STATUS_DLL_SLAVE_VALUE ro — No description provided for this field
0x37C PHY_STATUS_OF_IN_DELAY_VAL_SR1 — No description provided for this register
  [15:0] PHY_REG_STATUS_OF_IN_DELAY_VALUE ro — No description provided for this field
0x380 PHY_STATUS_OF_IN_DELAY_VAL_SR2 — No description provided for this register
  [10:0] PHY_REG_STATUS_OF_IN_DELAY_VALUE ro — No description provided for this field
0x384 PHY_STATUS_OF_OUT_DELAY_VAL_SR1 — No description provided for this register
  [15:0] PHY_REG_STATUS_OF_OUT_DELAY_VALUE ro — No description provided for this field
0x388 PHY_STATUS_OF_OUT_DELAY_VAL_SR2 — No description provided for this register
  [10:0] PHY_REG_STATUS_OF_OUT_DELAY_VALUE ro — No description provided for this field
0x38C PHY_DLL_LOCK_AND_SLAVE_VAL_SR — No description provided for this register
  [9] PHY_REG_STATUS_PHY_CTRL_DLL_LOCK ro — No description provided for this field
  [8:0] PHY_REG_STATUS_PHY_CTRL_DLL_SLAVE_VALUE ro — No description provided for this field
0x390 PHY_CTRL_OUTPUT_FILTER_SR — No description provided for this register
  [10:9] PHY_REG_STATUS_PHY_CTRL_OF_IN_LOCK_STATE ro — No description provided for this field
  [8:0] PHY_REG_STATUS_PHY_CTRL_OF_IN_DELAY_VALUE ro — No description provided for this field
0x398 PHY_RD_DQS_SLAVE_DLL_VAL_SR1 — No description provided for this register
  [15:0] PHY_STATUS_RD_DQS_SLAVE_DLL_VALUE ro — No description provided for this field
0x39C PHY_RD_DQS_SLAVE_DLL_VAL_SR2 — No description provided for this register
  [15:0] PHY_REG_STATUS_RD_DQS_SLAVE_DLL_VALUE ro — No description provided for this field
0x3A0 PHY_RD_DQS_SLAVE_DLL_VAL_SR3 — No description provided for this register
  [12:0] PHY_REG_STATUS_RD_DQS_SLAVE_DLL_VALUE ro — No description provided for this field
0x3A4 PHY_WR_DATA_SLAVE_DLL_VAL_SR1 — No description provided for this register
  [15:0] PHY_REG_STATUS_WR_DATA_SLAVE_DLL_VALUE ro — No description provided for this field
0x3A8 PHY_WR_DATA_SLAVE_DLL_VAL_SR2 — No description provided for this register
  fields as PHY_WR_DATA_SLAVE_DLL_VAL_SR1
0x3AC PHY_WR_DATA_SLAVE_DLL_VAL_SR3 — No description provided for this register
  [12:0] PHY_REG_STATUS_WR_DATA_SLAVE_DLL_VALUE ro — No description provided for this field
{0x3AC+4i} PHY_FIFO_WE_SLAVE_DLL_VAL_SR{i} (i=1..3) — No description provided for this register
  [15:0] PHY_REG_STATUS_FIFO_WE_SLAVE_DLL_VALUE ro — No description provided for this field
{0x3B8+4i} PHY_WR_DQS_SLAVE_DLL_VAL_SR{i} (i=1..3) — No description provided for this register
  [15:0] PHY_REG_STATUS_WR_DQS_SLAVE_DLL_VALUE ro — No description provided for this field
0x3C8 PHY_CTRL_SLAVE_DLL_VAL_SR — No description provided for this register
  [8:0] PHY_REG_STATUS_PHY_CTRL_SLAVE_DLL_VALUE ro — No description provided for this field
0x400 DDR_FIC_NB_ADDR_CR — No description provided for this register
  [15:0] DDR_FIC_NB_ADD — No description provided for this field
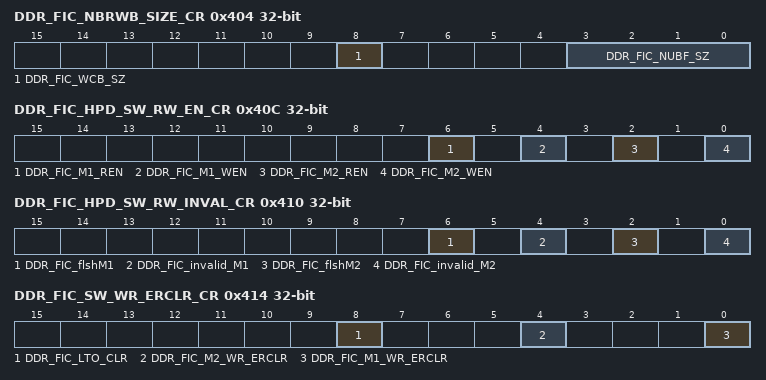
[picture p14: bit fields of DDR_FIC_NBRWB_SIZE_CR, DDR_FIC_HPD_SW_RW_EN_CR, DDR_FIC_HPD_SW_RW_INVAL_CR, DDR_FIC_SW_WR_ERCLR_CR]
0x404 DDR_FIC_NBRWB_SIZE_CR — No description provided for this register
  [8] DDR_FIC_WCB_SZ — No description provided for this field
  [3:0] DDR_FIC_NUBF_SZ — No description provided for this field
0x408 DDR_FIC_BUF_TIMER_CR — No description provided for this register
  [9:0] DDR_FIC_TIMER — No description provided for this field
0x40C DDR_FIC_HPD_SW_RW_EN_CR — No description provided for this register
  [6] DDR_FIC_M1_REN — No description provided for this field
  [4] DDR_FIC_M1_WEN — No description provided for this field
  [2] DDR_FIC_M2_REN — No description provided for this field
  [0] DDR_FIC_M2_WEN — No description provided for this field
0x410 DDR_FIC_HPD_SW_RW_INVAL_CR — No description provided for this register
  [6] DDR_FIC_flshM1 — No description provided for this field
  [4] DDR_FIC_invalid_M1 — No description provided for this field
  [2] DDR_FIC_flshM2 — No description provided for this field
  [0] DDR_FIC_invalid_M2 — No description provided for this field
0x414 DDR_FIC_SW_WR_ERCLR_CR — No description provided for this register
  [8] DDR_FIC_LTO_CLR — No description provided for this field
  [4] DDR_FIC_M2_WR_ERCLR — No description provided for this field
  [0] DDR_FIC_M1_WR_ERCLR — No description provided for this field
0x418 DDR_FIC_ERR_INT_ENABLE — No description provided for this register
  [1] SYR_SW_WR_ERR — No description provided for this field
  [0] SYR_HPD_WR_ERR — No description provided for this field
0x41C DDR_FIC_NUM_AHB_MASTERS_CR — No description provided for this register
  [4] CFG_NUM_AHB_MASTERS — No description provided for this field
0x420 DDR_FIC_HPB_ERR_ADDR_SR1 — No description provided for this register
  [15:0] DDR_FIC_M1_ERR_ADD ro — No description provided for this field
0x424 DDR_FIC_HPB_ERR_ADDR_SR2 — No description provided for this register
  fields as DDR_FIC_HPB_ERR_ADDR_SR1
0x428 DDR_FIC_SW_ERR_ADDR_SR1 — No description provided for this register
  [15:0] DDR_FIC_M2_ERR_ADD ro — No description provided for this field
0x42C DDR_FIC_SW_ERR_ADDR_SR2 — No description provided for this register
  fields as DDR_FIC_SW_ERR_ADDR_SR1
0x430 DDR_FIC_HPD_SW_WRB_EMPTY_SR — No description provided for this register
  [6] DDR_FIC_M1_RBEMPTY ro — No description provided for this field
  [4] DDR_FIC_M1_WBEMPTY ro — No description provided for this field
  [2] DDR_FIC_M2_RBEMPTY ro — No description provided for this field
  [0] DDR_FIC_M2_WBEMPTY ro — No description provided for this field
0x434 DDR_FIC_SW_HPB_LOCKOUT_SR — No description provided for this register
  [8] DDR_FIC_LCKTOUT ro — No description provided for this field
  [6] DDR_FIC_M2_WDSBL_DN ro — No description provided for this field
  [4] DDR_FIC_M2_RDSBL_DN ro — No description provided for this field
  [2] DDR_FIC_M1_WDSBL_DN ro — No description provided for this field
  [0] DDR_FIC_M1_RDSBL_DN ro — No description provided for this field
0x438 DDR_FIC_SW_HPD_WERR_SR — No description provided for this register
  [8] DDR_FIC_M1_WR_ERR ro — No description provided for this field
  [0] DDR_FIC_M2_WR_ERR ro — No description provided for this field
0x43C DDR_LOCK_TIMEOUTVAL_CR1 — No description provided for this register
  [15:0] CFGR_LOCK_TIMEOUT_REG — No description provided for this field
0x440 DDR_LOCK_TIMEOUTVAL_CR2 — No description provided for this register
  fields as DDR_LOCK_TIMEOUTVAL_CR1
0x444 DDR_FIC_LOCK_TIMEOUT_EN_CR — No description provided for this register
  [0] CFGR_LOCK_TIMEOUT_EN — No description provided for this field
0x448 DDR_FIC_RDWR_ERR_SR — No description provided for this register
  [5:0] DDR_FIC_CFG_RDWR_ERR_SR ro — No description provided for this field
